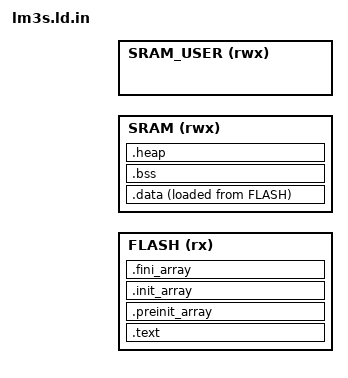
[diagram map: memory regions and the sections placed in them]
/******************************************************************************
 *
 * standalone.ld - Linker script for applications using startup.c 
 *
 *****************************************************************************/
ENTRY(reset_handler) 
MEMORY
{
    FLASH (rx) : ORIGIN = __FLASH_ORIGIN, LENGTH = __KFLASHMEM_SIZE
    SRAM (rwx) : ORIGIN = __RAM1_BASE, LENGTH = __KRAMMEM_SIZE
    SRAM_USER (rwx) : ORIGIN = (__RAM1_BASE + __KRAMMEM_SIZE), LENGTH = (__RAM1_SIZE - __KRAMMEM_SIZE)
}

__StackTop = ORIGIN(SRAM) + LENGTH(SRAM) - 4;
 
SECTIONS
{
    .text :
    {
        KEEP(*(.vectors))
        *(.text*)
        *(.rodata*)
    } > FLASH
	/* C++ Static constructors/destructors, also used for __attribute__
	 * ((constructor)) and the likes */
	.preinit_array : {
		. = ALIGN(4);
		__preinit_array_start = .;
		KEEP (*(.preinit_array))
		__preinit_array_end = .;
	} > FLASH
	.init_array : {
		. = ALIGN(4);
		__init_array_start = .;
		KEEP (*(SORT(.init_array.*)))
		KEEP (*(.init_array))
		__init_array_end = .;
	} > FLASH
	.fini_array : {
		. = ALIGN(4);
		__fini_array_start = .;
		KEEP (*(.fini_array))
		KEEP (*(SORT(.fini_array.*)))
		__fini_array_end = .;
	} > FLASH
 
    .data :
    {
        _etext = LOADADDR(.data);
        _data = .;
        *(vtable)
        *(.data*)
        _edata = .;
    } > SRAM AT > FLASH
	_data_loadaddr = LOADADDR(.data);
 
    .bss :
    {
        _bss = .;
        *(.bss*)
        *(COMMON)
        . = ALIGN(32 / 8);
        _ebss = .;
        PROVIDE (end = .);
    } > SRAM

    .heap :
    {
        /* heap starts after BSS */
        PROVIDE(_heap_start = _ebss );
    } > SRAM
}

PROVIDE(_stack = ORIGIN(SRAM) + LENGTH(SRAM));
PROVIDE(_user_heap_start = ORIGIN(SRAM_USER));
PROVIDE(_user_heap_end = ORIGIN(SRAM_USER) + LENGTH(SRAM_USER));

